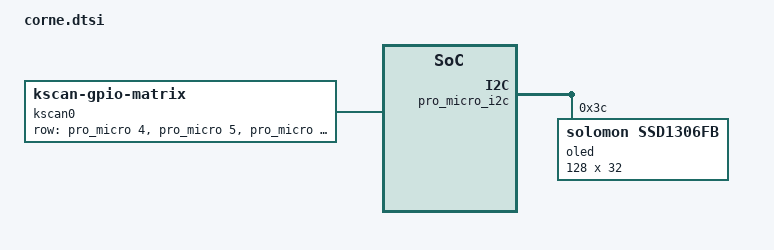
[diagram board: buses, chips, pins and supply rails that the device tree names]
/*
 * Copyright (c) 2020 Pete Johanson
 *
 * SPDX-License-Identifier: MIT
 */

#include <dt-bindings/zmk/matrix_transform.h>

#include <layouts/foostan/corne.dtsi>


/ {
    chosen {
        zephyr,display = &oled;
        zmk,kscan = &kscan0;
        zmk,physical-layout = &foostan_corne_6col_layout;
    };

    kscan0: kscan {
        compatible = "zmk,kscan-gpio-matrix";
        wakeup-source;

        diode-direction = "col2row";
        row-gpios
            = <&pro_micro 4 (GPIO_ACTIVE_HIGH | GPIO_PULL_DOWN)>
            , <&pro_micro 5 (GPIO_ACTIVE_HIGH | GPIO_PULL_DOWN)>
            , <&pro_micro 6 (GPIO_ACTIVE_HIGH | GPIO_PULL_DOWN)>
            , <&pro_micro 7 (GPIO_ACTIVE_HIGH | GPIO_PULL_DOWN)>
            ;

    };

    // TODO: per-key RGB node(s)?
};

&pro_micro_i2c {
    status = "okay";

    oled: ssd1306@3c {
        compatible = "solomon,ssd1306fb";
        reg = <0x3c>;
        width = <128>;
        height = <32>;
        segment-offset = <0>;
        page-offset = <0>;
        display-offset = <0>;
        multiplex-ratio = <31>;
        segment-remap;
        com-invdir;
        com-sequential;
        inversion-on;
        prechargep = <0x22>;
    };
};
